# ESP32S31_RADIO register map
Vendor: Espressif; Series: ESP32-S31; File version: 3.52
Registers are 32-bit, read-write, no defined reset value unless marked. A register's access mark holds for its fields unless they carry their own. Offsets are from the block's base; [hi:lo] are bit positions; lines under a group give offsets from that group; {n}, {i} and the like mark numbered series.

## WIFI_MAC_BEAMFORMING_FEEDBACK_TEST — Test-only beamforming-feedback selector written by complete esp_test_bf_set_feedback. The write transforms and selector branches are exact; the public meaning of selector values zero through sixteen is not present in the archive, so only bounded functional names are assigned.
Base 0x20104E00
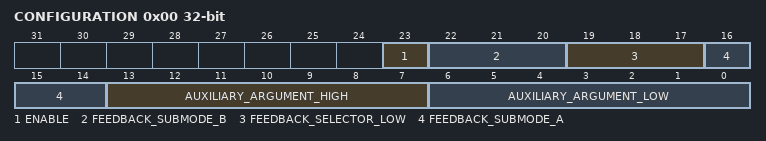
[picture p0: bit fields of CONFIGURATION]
0x00 CONFIGURATION — A zero enable argument clears ENABLE only. A nonzero argument first sets ENABLE, clears FEEDBACK_SUBMODE_B, replaces both seven-bit auxiliary arguments, then applies selector-dependent updates to the remaining submode fields. Selector sixteen replaces the complete word with ENABLE plus FEEDBACK_SUBMODE_B value one.
  [23] ENABLE — A nonzero enable argument sets this bit; zero clears it.
  [22:20] FEEDBACK_SUBMODE_B — Three-bit selector-dependent field. The common enabled prefix clears it; selectors twelve and sixteen publish one.
  [19:17] FEEDBACK_SELECTOR_LOW — For selectors zero through seven this field receives the three-bit selector. The higher selector classes update it only partially or clear it.
  [16:14] FEEDBACK_SUBMODE_A — Three-bit selector-dependent field. Complete branches publish one for selector thirteen and five for selector fourteen.
  [13:7] AUXILIARY_ARGUMENT_HIGH — High seven-bit argument passed as esp_test_bf_set_feedback argument three.
  [6:0] AUXILIARY_ARGUMENT_LOW — Low seven-bit argument passed as esp_test_bf_set_feedback argument two.

## WIFI_MAC_HE_OBSS_NARROW_BAND_RU — Complete hal_he_disable_obss_narrow_bw_ru writes either all ones or zero into the twenty-bit bitmap and independently sets or clears a five-bit class group and the global disable bit. The leaf name proves the aggregate disable function; individual bitmap/class identities remain approximate.
Base 0x20104E9C
0x00 DISABLE_BITMAP — Twenty-bit OBSS narrow-band RU disable bitmap written as 0xfffff when disabled and zero when enabled.
  [19:0] VALUE
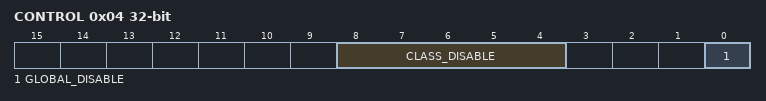
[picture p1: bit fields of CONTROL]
0x04 CONTROL — The complete leaf updates CLASS_DISABLE bits first and GLOBAL_DISABLE second through independent fresh-read RMWs.
  [8:4] CLASS_DISABLE — Approximate functional name for the five bits toggled together by hal_he_disable_obss_narrow_bw_ru.
  [0] GLOBAL_DISABLE

## WIFI_MAC_TX_POWER_INIT — Complete hal_init_tx_pwr consumes 43 two-byte PHY power results, then complete TB, immediate-response and TB-RU leaves publish 56 ordered fresh-read RMW edges. Runtime partial-RU get/set APIs select the same packed fields by the raw Trigger RU allocation. Values are PHY gain-table indices, not dBm.
Base 0x20104408
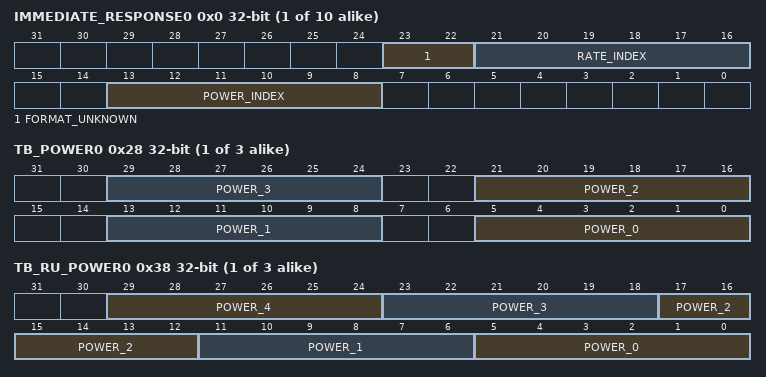
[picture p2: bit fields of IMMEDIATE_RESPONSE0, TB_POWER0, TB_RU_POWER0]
{0x0+4i} IMMEDIATE_RESPONSE{i} (i=0..9) — Ten immediate-response command words. Complete hal_init_imrsp_power separately replaces format, rate and power-index fields in that order.
  [23:22] FORMAT_UNKNOWN — Zero for the six legacy response words and two for the four HE response words.
  [21:16] RATE_INDEX
  [13:8] POWER_INDEX — PHY gain-table index selected for the response rate; not dBm.
{0x28+4i} TB_POWER{i} (i=0..2) — Three trigger-based power words populated from rates 16 through 25. Each used six-bit field is updated through a separate RMW.
  [8n+5:8n] POWER_{n} (n=0..3)
0x34 TB_RU_POWER_TAIL — Complete hal_init_tb_ru_power publishes the unadjusted rate-16 power at raw Trigger RU selector 61. Complete runtime get/set leaves address this same six-bit field; selector 62 is rejected.
  [29:24] POWER_INDEX
{0x38+4i} TB_RU_POWER{i} (i=0..2) — Packed trigger-based resource-unit power deltas selected by raw Trigger RU allocation. Complete runtime get/set jump tables admit only selectors 0 through 8, 37 through 40, 53, 54 and 61; the first fifteen selectors occupy these packed words and selector 61 occupies TB_RU_POWER_TAIL.
  [6n+5:6n] POWER_{n} (n=0..4)
